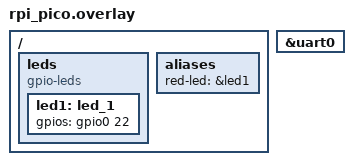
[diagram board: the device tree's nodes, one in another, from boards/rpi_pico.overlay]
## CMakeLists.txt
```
# SPDX-License-Identifier: Apache-2.0

cmake_minimum_required(VERSION 3.20.0)

find_package(Zephyr REQUIRED HINTS $ENV{ZEPHYR_BASE})

## Note some cmake functions must be called before cmake project() directive - TMH
project(rpi-pico-exploration)


##----------------------------------------------------------------------
## - SECTION - application files
##----------------------------------------------------------------------

# 2023-06-14 NOTE, following `modules/hal/rpi_pico` paths support header
#  file dependencies of pulled in `uart_advanced.c` source file:

target_include_directories(app PRIVATE
  "${CMAKE_CURRENT_SOURCE_DIR}/include"
  "${CMAKE_CURRENT_SOURCE_DIR}/../modules/hal/rpi_pico/src/rp2_common/hardware_irq/include"
  "${CMAKE_CURRENT_SOURCE_DIR}/../modules/hal/rpi_pico/src/common/pico_stdlib/include"
  "${CMAKE_CURRENT_SOURCE_DIR}/../modules/hal/rpi_pico/src/rp2_common/pico_stdio/include"
  "${CMAKE_CURRENT_SOURCE_DIR}/../modules/hal/rpi_pico/src/common/pico_time/include"
  "${CMAKE_CURRENT_SOURCE_DIR}/../modules/hal/rpi_pico/src/common/pico_sync/include"
  "${CMAKE_CURRENT_SOURCE_DIR}/../modules/hal/rpi_pico/src/rp2040/hardware_regs/include"
# Following include path pulls in RPi Pico "hardware/uart.h" but not sufficient to provide defs to linker
# for uart_is_readable(), uart_getc(), uart_is_writable(), uart_putc():
  "${CMAKE_CURRENT_SOURCE_DIR}/../modules/hal/rpi_pico/src/rp2_common/hardware_uart/include"
)

# ./modules/hal/rpi_pico/src/rp2_common/hardware_irq/include/hardware/irq.h

target_sources(app PRIVATE
  src/main.c
  src/thread-led.c
  src/thread-hello-dma.c
  src/local_rpi_platform_base.c
  src/thread-simple-cli.c
  src/commands.c
  ${CMAKE_CURRENT_SOURCE_DIR}/../modules/hal/rpi_pico/src/rp2_common/hardware_irq/irq.c
  src/uart_advanced.c
  src/diagnostics.c
)


##----------------------------------------------------------------------
## - SECTION - RPi Pico SDK dependencies
##----------------------------------------------------------------------

# ../modules/hal/rpi_pico/src/host/pico_platform/include/pico/platform.h

# 2023-04-19 Note second, third and fourth paths inform build system
#  where Pico SDK pound includes can find their expressed header files:

target_include_directories(app PRIVATE
  "../modules/hal/rpi_pico/src/"
  "../modules/hal/rpi_pico/src/rp2_common/hardware_dma/include/"
  "../modules/hal/rpi_pico/src/rp2_common/hardware_claim/include/"
# Only header file here is platform.h:
  "../modules/hal/rpi_pico/src/host/pico_platform/include/pico/"
)

# ../modules/hal/rpi_pico/src/rp2_common/hardware_dma/dma.c

# Pico SDK source file platform_base.c provides:  void panic(const char *fmt, ...) {

cmake_path(SET RPI_HARDWARE_ABSTRACTION_LAYER_DIR "../modules/hal/rpi_pico")

target_sources(app PRIVATE
  "${RPI_HARDWARE_ABSTRACTION_LAYER_DIR}/src/rp2_common/hardware_dma/dma.c"
  "${RPI_HARDWARE_ABSTRACTION_LAYER_DIR}/src/rp2_common/hardware_claim/claim.c"
)

#  "${RPI_HARDWARE_ABSTRACTION_LAYER_DIR}/src/host/pico_platform/platform_base.c"
```

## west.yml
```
manifest:
  remotes:
    - name: zephyrproject-rtos
      url-base: https://github.com/zephyrproject-rtos

  projects:
    - name: zephyr
      repo-path: zephyr
      remote: zephyrproject-rtos
      revision: v3.3.0
      import: true

    # Kionix driver work repository, name of remote repository followed by name of local dir into which to clone:
    - name: zephyr-driver-work-v2
      path: kionix-drivers
      revision: main
      url: https://github.com/tedhavelka/zephyr-driver-work-v2

    # RaspberryPi Pico SDK, for DMA and SPI driver study . . .
    - name: pico-sdk
      path: pico-sdk
      revision: 1.4.0
      url: https://github.com/raspberrypi/pico-sdk

#    # RaspberryPi Pico examples
#    - name: pico-examples
#      path: pico-examples
#      revision: sdk-1.4.0
#      url: git@github.com:raspberrypi/pico-examples

  self:
    # This repository should be cloned to 
    path: rpi-pico-zephyr-exploration
```

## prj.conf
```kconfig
CONFIG_LOG=y

CONFIG_GPIO=y

# 2022-08-05 FRI
# https://docs.zephyrproject.org/latest/samples/drivers/led_ws2812/README.html
# https://docs.zephyrproject.org/latest/kconfig.html#CONFIG_WS2812_STRIP_GPIO

CONFIG_SOC_SERIES_NRF51X=n
CONFIG_LED_STRIP=y
CONFIG_LED_STRIP_LOG_LEVEL_DBG=y
CONFIG_WS2812_STRIP=y
# CONFIG_WS2812_STRIP_DRIVER=y    <-- not a defined Kconfig symbol - TMH
CONFIG_WS2812_STRIP_GPIO=y

# 2023-06-14 WED . . .
CONFIG_SERIAL=y
#CONFIG_SERIAL_SUPPORT_ASYNC=y  . . . symbol has no prompt, must be selected by other symbol
CONFIG_UART_ASYNC_API=y
```

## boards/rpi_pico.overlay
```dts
/*
 * Copyright (c) 2019, Nordic Semiconductor ASA
 *
 * SPDX-License-Identifier: Apache-2.0
 */

#include <zephyr/dt-bindings/gpio/gpio.h>
#include <zephyr/dt-bindings/led/led.h>

/* https://developer.toradex.com/linux-bsp/how-to/device-tree/device-tree-customization/ */

/*
 *  Break out an extra LED on general purpose I/O pin 7:
 */

/ {
        leds {
                compatible = "gpio-leds";
                led1: led_1 {
                        gpios = <&gpio0 22 GPIO_ACTIVE_HIGH>;
                };
        };

        aliases {
                red-led = &led1;
        };
};

// - DEV 0615 - attempting to assure we have device tree nodelabel to reference in DT_NODELABEL() macro:
uart_0: &uart0 {
        status = "okay";
};
```

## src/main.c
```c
/*
 *  Copyright (c) 2023 Neela Nurseries
 *
 *  SPDX-License-Identifier: Apache-2.0
 *
 *  Project:  https://github.com/tedhavelka/rpi-pico-zephyr-exploration
 *
 *  File:  main.c
 */



//----------------------------------------------------------------------
// - SECTION - includes, NEED to review line by line which are needed - TMH
//----------------------------------------------------------------------

#include <errno.h>
#include <string.h>
#define LOG_LEVEL 4
#include <zephyr/logging/log.h>
LOG_MODULE_REGISTER(main);

#include <zephyr/kernel.h>
#include <zephyr/drivers/gpio.h>
#include <zephyr/device.h>

#include <zephyr/drivers/led_strip.h>   // to provide ...

// Pico SDK headers:
// Following header from ../modules/hal/rpi_pico/src/rp2040/hardware_regs/include/hardware/regs/intctrl.h
#include "hardware/regs/intctrl.h" // to provide UART0_IRQ

// Following Pico-SDK header provides several low level, static in-line functions:
#include "hardware/uart.h"         // to provide uart_is_readable, uart_getc, uart_is_writable, uart_putc

// 2022-08-04 added for simple factoring during early UART tests:
#include "main.h"
#include "development-defines.h"
#include "thread-led.h"
#include "thread-hello-dma.h"
#include "thread-simple-cli.h"
#include "thread-uart-advanced.h"
#include "uart-advanced.h"



//----------------------------------------------------------------------
// - SECTION - defines
//----------------------------------------------------------------------

// 1000 msec = 1 sec
#define SLEEP_TIME_MS 15000

// The devicetree node identifier for the "led0" alias.
#define LED0_NODE DT_ALIAS(led0)

// Following symbol sets a modest upper bound on periodic "mark" message, akin to heartbeat LED:
#define MARK_CYCLE_LENGTH 6

/*
 * A build error on this line means your board is unsupported.
 * See the sample documentation for information on how to fix this.
 */

#ifdef DEV_0805_KEEP_BLINKY_CODE_ENABLED
static const struct gpio_dt_spec led = GPIO_DT_SPEC_GET(LED0_NODE, gpios);
#endif

#ifdef DEV_0805__WS2812_BRING_UP_WORK_ON_RP2040

// --- DEV BEGIN :: WS2812 test ---
//
// Source file:  ~/projects-sandbox/workspace-for-rpi/zephyr/samples/drivers/led_ws2812/src/main.c

#define STRIP_NODE              DT_ALIAS(led_strip)
#define STRIP_NUM_PIXELS        DT_PROP(DT_ALIAS(led_strip), chain_length)

#define DELAY_TIME K_MSEC(50)

#define RGB(_r, _g, _b) { .r = (_r), .g = (_g), .b = (_b) }

static const struct led_rgb colors[] = { 
        RGB(0x0f, 0x00, 0x00), /* red */
        RGB(0x00, 0x0f, 0x00), /* green */
        RGB(0x00, 0x00, 0x0f), /* blue */
};

struct led_rgb pixels[STRIP_NUM_PIXELS];

static const struct device *strip = DEVICE_DT_GET(STRIP_NODE);

// --- DEV END :: WS2812 test ---
#endif // DEV_0805__WS2812_BRING_UP_WORK_ON_RP2040

static bool global_flag_fsv = 0;


//----------------------------------------------------------------------
// - SECTION - routines
//----------------------------------------------------------------------

extern int main_for_advanced_uart_init(void);

// From Pico SDK sample:
static int chars_rxed = 0;

static void rpi_pico_uart1_isr(const struct device *dev)
{
    ARG_UNUSED(dev);

    global_flag_fsv = 1;

#define UART_ID uart1
// * * * * * * * * * * * * * * * * * * * * * * * * * * * * * * * * * * *
// From Pico SDK sample:
    while (uart_is_readable(UART_ID))
    {
        uint8_t ch = uart_getc(UART_ID);

        // Can we send it back?
        if (uart_is_writable(UART_ID))
        {
            // Change it slightly first!
            ch++;
            uart_putc(UART_ID, ch);
        }
        chars_rxed++;
    }
// * * * * * * * * * * * * * * * * * * * * * * * * * * * * * * * * * * *
}

void main(void)
{
    int rstatus = 0;

#if 1 //
    uint32_t count_for_mark_messages = 0;
    char lbuf[SIZE_OF_TEN_BYTES] = { 0 };

    if (!device_is_ready(led.port)) {
        return;
    }

    rstatus = gpio_pin_configure_dt(&led, GPIO_OUTPUT_ACTIVE);
    if (rstatus < 0) {
        return;
    }

    memset(lbuf, 0, SIZE_OF_TEN_BYTES);

// NEED to capture return value from this routine call:
    rstatus = thread_led__initialize();

#ifdef DEV_0819_ENABLE_PICO_HELLO_DMA_CODE
    thread_hello_dma__initialize();
#endif

#if 1 // - DEV 0613 -
    rstatus |= initialize_thread_simple_cli();
    k_msleep(500);
#endif // - DEV 0613 -

#if 1
#define DEV_0615_DEFAULT_PRIORITY 1
#define UART_NODE DT_NODELABEL(uart_0)
    printk("- main.c - calling IRQ_CONNECT(), will send mark after call . . .\n");
    IRQ_CONNECT(UART1_IRQ, DEV_0615_DEFAULT_PRIORITY, rpi_pico_uart1_isr, DEVICE_DT_GET(UART_NODE), 0);
    printk("- MARK 0 -\n");
    k_msleep(1500);
#endif
#if 0
    printk("- DEV 0615 - symbols UART0_IRQ, UART1_IRQ assigned valueos of %u, %u\n",
      UART0_IRQ, UART1_IRQ);
#endif

// - DEV 0614 -
    printk("- main.c - calling Pico UART DMA sample code . . .\n");
    main_for_advanced_uart_init();
    k_msleep(500);
    printk("- MARK 1 -\n");
//    initialize_thread_uart_advanced();  . . . build time error regarding conflicting defines of arch_irq_is_enabled or similar
// - DEV 0614 -


    while (1)
    {
#ifdef DEV_0808__BLINK_FROM_MAIN_NOT_FROM_THREAD
        ret = gpio_pin_toggle_dt(&led);

        if (ret < 0) {
            return;
        }
#endif

        if ( count_for_mark_messages < MARK_CYCLE_LENGTH )
        {
            count_for_mark_messages++;
        }
        else
        {
            count_for_mark_messages = 1;
            memset(lbuf, 0, SIZE_OF_TEN_BYTES);
        }
         
        memset(lbuf, '.', count_for_mark_messages);

        printk("- MARK 0614 -");
        printk("%s", lbuf);
        printk("\n\r");

        k_msleep(SLEEP_TIME_MS);
    }
#endif

#ifdef DEV_0805__WS2812_BRING_UP_WORK_ON_RP2040
    size_t cursor = 0, color = 0;
    int rc;

    if (device_is_ready(strip)) {
        LOG_INF("Found LED strip device %s", strip->name);
    } else {
        LOG_ERR("LED strip device %s is not ready", strip->name);
        return;
    }

    LOG_INF("Displaying pattern on strip");
    while (1) {
        memset(&pixels, 0x00, sizeof(pixels));
        memcpy(&pixels[cursor], &colors[color], sizeof(struct led_rgb));
        rc = led_strip_update_rgb(strip, pixels, STRIP_NUM_PIXELS);

        if (rc) {
            LOG_ERR("couldn't update strip: %d", rc);
        }

        cursor++;
        if (cursor >= STRIP_NUM_PIXELS) {
            cursor = 0;
            color++;
            if (color == ARRAY_SIZE(colors)) {
                color = 0;
            }
        }

        k_msleep(SLEEP_TIME_MS);
    }
#endif // DEV_0805__WS2812_BRING_UP_WORK_ON_RP2040

}



// --- EOF ---
```

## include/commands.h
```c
#ifndef _RPI_PICO_EXPLORATION__COMMANDS_H
#define _RPI_PICO_EXPLORATION__COMMANDS_H

uint32_t cli_set_unset_dma_demo(const char* args);

#endif // _RPI_PICO_EXPLORATION__COMMANDS_H
```

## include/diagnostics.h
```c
#ifndef DIAGNOSTICS_H
#define DIAGNOSTICS_H

/*
 * Copyright (c) 2021 Neela Nurseries
 *
 * SPDX-License-Identifier: Apache-2.0
 */

// NOTE:  developers make sure last entry does not exceed integer value of 31 - TMH
enum nn_diagnostic_levels
{
    _NN_DIAG_SILENT,
    _NN_DIAG_ERRORS,
    _NN_DIAG_WARNINGS,
    _NN_DIAG_INFO,
    _NN_DIAG_LEVEL__LAST_ENTRY
};

#define KD_DIAG_SILENT   ( 1 << _NN_DIAG_SILENT )
#define KD_DIAG_ERRORS   ( 1 << _NN_DIAG_ERRORS )
#define KD_DIAG_WARNINGS ( 1 << _NN_DIAG_WARNINGS )
#define KD_DIAG_INFO     ( 1 << _NN_DIAG_INFO )

#define DIAG_OFF       KD_DIAG_SILENT
#define DIAG_MINIMAL   KD_DIAG_ERRORS
#define DIAG_NORMAL  ( KD_DIAG_ERRORS | KD_DIAG_WARNINGS )
#define DIAG_VERBOSE ( KD_DIAG_ERRORS | KD_DIAG_WARNINGS | KD_DIAG_INFO )


// NOTE:  developers make sure last entry does not exceed integer value of 31 - TMH
enum nn_diagnostic_message_options
{
    _NN_DIAG_TO_DEFAULT_UART = _NN_DIAG_LEVEL__LAST_ENTRY,
    _NN_DIAG_TO_CLI_UART,
    _NN_DIAG_OPTION__LAST_ENTRY
};

#define KD_DIAG_OPTION_TO_DEFAULT_UART ( 1 << _NN_DIAG_TO_DEFAULT_UART )
#define KD_DIAG_OPTION_TO_CLI_UART     ( 1 << _NN_DIAG_TO_CLI_UART )


// "Project level diagnostics" is project wide default diagnostics setting:

//#define PROJECT_DIAG_LEVEL DIAG_NORMAL // DIAG_OFF
//#define PROJECT_DIAG_LEVEL DIAG_OFF // DIAG_NORMAL
#define PROJECT_DIAG_LEVEL ( DIAG_NORMAL | KD_DIAG_OPTION_TO_CLI_UART )



//----------------------------------------------------------------------
// - SECTION - buffer sizes
//----------------------------------------------------------------------

#define SIZE_OF_MESSAGE_SHORT (80)
#define SIZE_OF_MESSAGE_MEDIUM (160)
#define DEFAULT_MESSAGE_SIZE (256)



//----------------------------------------------------------------------
// - SECTION - Function prototypes
//----------------------------------------------------------------------

void dmsg(const char* message, int option);



#endif // _DIAGNOSTICS_H
```

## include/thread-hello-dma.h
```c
#ifndef _RP2040_EXPLORATION__THREAD_HELLO_DMA
#define _RP2040_EXPLORATION__THREAD_HELLO_DMA


#include <stdbool.h>

int thread_hello_dma__initialize(void);

//void thread_hello_dma__entry_point(void* arg1, void* arg2, void* arg3);

void thread_hello_dma_set_unset_demo(bool option);


#endif // _RP2040_EXPLORATION__THREAD_HELLO_DMA
```

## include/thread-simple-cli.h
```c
#ifndef _THREAD_SIMPLE_CLI
#define _THREAD_SIMPLE_CLI


int initialize_thread_simple_cli(void);

// routine to send character stream to arbitrary, non-Zephyr-chosen UART:
uint32_t printk_cli(const char* output);

// routine to share arguments counted in latest command input:
uint32_t argument_count_from_cli_module(void);

uint32_t arg_n(const uint32_t requested_arg, char* return_arg);

uint32_t arg_is_decimal(const uint32_t index_to_arg, int* value_to_return);

uint32_t dec_value_at_arg_index(const uint32_t index_to_arg);


// 2021-11-18 - command factoring work:
#define SIZE_COMMAND_TOKEN   (128)
#define SUPPORTED_ARG_LENGTH (16)

// Note, space permitting we'll store up to ten user commands in a ring buffer:
#define SIZE_COMMAND_HISTORY (10)

// Note, for now we support command line up to 256 characters:
#define SIZE_COMMAND_INPUT_SUPPORTED (256)

// Note, we start with support for passing up to ten args to a CLI command herein:
#define MAX_COUNT_SUPPORTED_ARGS (10)


#endif // _THREAD_SIMPLE_CLI
```

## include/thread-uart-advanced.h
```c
#ifndef _THREAD_UART_ADVANCED_H
#define _THREAD_UART_ADVANCED_H


int initialize_thread_uart_advanced(void);


#endif // _THREAD_UART_ADVANCED_H
```

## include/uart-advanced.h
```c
#ifndef _UART_ADVANCED_H
#define _UART_ADVANCED_H

void on_uart_rx();

#endif // _UART_ADVANCED_H
```

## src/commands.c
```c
#include <stdbool.h>               // to provide C 'bool' type definition
#include <stdint.h>                // to provide define of uint32_t

#include <zephyr/toolchain/gcc.h>  // to provide ARG_UNUSED() function like macro

#include "thread-hello-dma.h"


uint32_t cli_set_unset_dma_demo(const char* args)
{
    ARG_UNUSED(args);

    thread_hello_dma_set_unset_demo(false);

    return 0;
}
```

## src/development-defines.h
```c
#ifndef _RP2040_EXPLORE__DEVELOPMENT_DEFINES
#define _RP2040_EXPLORE__DEVELOPMENT_DEFINES



#define DEV_0805_KEEP_BLINKY_CODE_ENABLED
//#define DEV_0808__BLINK_FROM_MAIN_NOT_FROM_THREAD
#define DEV_0805__WS2812_BRING_UP_WORK_ON_RP2040



#endif // _RP2040_EXPLORE__DEVELOPMENT_DEFINES
```

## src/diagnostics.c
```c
/*
 * Copyright (c) 2021, 2023 Neela Nurseries
 *
 * SPDX-License-Identifier: Apache-2.0
 */


// #include <sys/printk.h>
#include <stdint.h>

#include "diagnostics.h"

#include "thread-simple-cli.h"



/*
 *----------------------------------------------------------------------
 * @brief     Wrapper function about Zephyr printk().
 * @purpose   To provide easy way to disable messages on chosen UART
 *            peripheral for Zephyr console, shell-uart, uart-mcumgr
 *            and similar.           
 *----------------------------------------------------------------------
 */

void dmsg(const char* message, int option)
{
    if (option == 0)
    {
        return;
    }

    if ( 1 )
    {
        printk_cli(message);
    }
}



// --- EOF ---
```

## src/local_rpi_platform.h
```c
#ifndef LOCAL_RPI_PLATFORM_H
#define LOCAL_RPI_PLATFORM_H


#ifndef _MSC_VER
#ifndef __noreturn
#define __noreturn __attribute((noreturn))
#endif

#ifndef __unused
#define __unused __attribute__((unused))
#endif

#ifndef __noinline
#define __noinline __attribute__((noinline))
#endif

#ifndef __aligned
#define __aligned(x) __attribute__((aligned(x)))
#endif

#define PICO_WEAK_FUNCTION_DEF(x) _Pragma(__STRING(weak x))
#define PICO_WEAK_FUNCTION_IMPL_NAME(x) x

#else
#ifndef __noreturn
#define __noreturn __declspec(noreturn)
#endif

#ifndef __unused
#define __unused
#endif

#ifndef __noinline
#define __noinline __declspec(noinline)
#endif

#ifndef __aligned
#define __aligned(x) __declspec(align(x))
#endif

#ifndef __CONCAT
#define __CONCAT(x,y) x ## y
#endif

#define __thread __declspec( thread )

#define PICO_WEAK_FUNCTION_DEF(x) __pragma(comment(linker, __STRING(/alternatename:_##x=_##x##__weak)));
#define PICO_WEAK_FUNCTION_IMPL_NAME(x) x ## __weak

static __noreturn void __builtin_unreachable() {
}

#include <intrin.h>
#define __builtin_clz __lzcnt
#endif


#endif // LOCAL_RPI_PLATFORM_H
```

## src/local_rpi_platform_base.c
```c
/*
 * Copyright (c) 2020 Raspberry Pi (Trading) Ltd.
 *
 * SPDX-License-Identifier: BSD-3-Clause
 */
#include <stdarg.h>
#include <stdio.h>

#include "pico.h"

// 2022-08-25 THU - amendment by Ted, testing to see whether resolves build error
//  seemingly related to symbol PICO_WEAK_FUNCTION_DEF:
//#include <platform.h>
#include "local_rpi_platform.h"
#include "local_rpi_platform_base.h"



// - DEV 0420 START ----------------------------------------------------
#if 0

PICO_WEAK_FUNCTION_DEF(tight_loop_contents)

void PICO_WEAK_FUNCTION_IMPL_NAME(tight_loop_contents)() {

}

#endif // 0
// - DEV 0420 END ------------------------------------------------------

void __noreturn panic_unsupported() {
    panic("not supported");
}

void hard_assertion_failure(void) {
    panic("Hard assert");
}

void panic(const char *fmt, ...) {
    va_list args;

    puts("*** PANIC ***\n");
    if (fmt) {
        va_start(args, fmt);
        vprintf(fmt, args);
        va_end(args);
    }

    puts("\n");

    __breakpoint();
}

#if 0 // already defined somewhere else - TMH
void __breakpoint() {
    #ifdef _MSC_VER
        __debugbreak();
    #else
        __builtin_trap();
    #endif
}
#endif // already defined somewhere else
```

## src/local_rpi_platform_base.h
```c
#ifndef LOCAL_RPI_PLATFORM_BASE_H
#define LOCAL_RPI_PLATFORM_BASE_H

void panic(const char *fmt, ...);

#endif // LOCAL_RPI_PLATFORM_BASE_H
```
